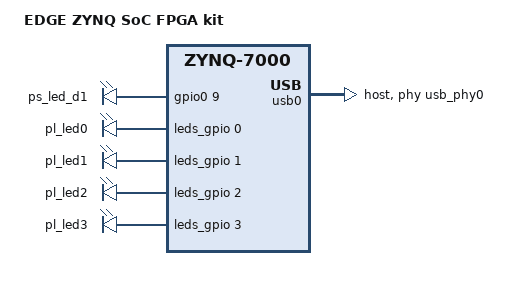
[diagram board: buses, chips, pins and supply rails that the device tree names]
/include/ "system-conf.dtsi"
/*
 * EDGE ZYNQ SoC FPGA kit (Z7-10 / Z7-20), V3 board
 * - USB0 host on connector J3 (jumpers J6 and J7 fitted), ULPI PHY, reset on MIO 46
 * - Ethernet PHY: no phy-handle, the driver scans MDIO (RTL8211F on V3, RTL8211E on V1/V2);
 *   phy-mode rgmii-id comes from the hardware description
 * - PS LED D1 on MIO 9: heartbeat; PL LEDs on the AXI GPIO at 0x41200000
 */
/ {
	model = "EDGE ZYNQ SoC FPGA kit";
	compatible = "inventlogics,edge-zynq", "xlnx,zynq-7000";

	usb_phy0: phy0@e0002000 {
		compatible = "ulpi-phy";
		#phy-cells = <0>;
		reg = <0xe0002000 0x1000>;
		view-port = <0x0170>;
		drv-vbus;
	};

	leds {
		compatible = "gpio-leds";
		ps-led-d1 {
			label = "ps_led_d1";
			gpios = <&gpio0 9 0>;
			linux,default-trigger = "heartbeat";
		};
		pl-led0 {
			label = "pl_led0";
			gpios = <&leds_gpio 0 0>;
			default-state = "off";
		};
		pl-led1 {
			label = "pl_led1";
			gpios = <&leds_gpio 1 0>;
			default-state = "off";
		};
		pl-led2 {
			label = "pl_led2";
			gpios = <&leds_gpio 2 0>;
			default-state = "off";
		};
		pl-led3 {
			label = "pl_led3";
			gpios = <&leds_gpio 3 0>;
			default-state = "off";
		};
	};
};

&usb0 {
	dr_mode = "host";
	usb-phy = <&usb_phy0>;
};

&sdhci0 {
	disable-wp;
	u-boot,dm-pre-reloc;
};

&uart0 {
	u-boot,dm-pre-reloc;
};
